# M4K0A register map
File version: 0.1
Registers are 32-bit, read-write, reset 0x0 unless marked. A register's access mark holds for its fields unless they carry their own. Offsets are from the block's base; [hi:lo] are bit positions; {n}, {i} and the like mark numbered series.

## SIWD
Base 0x400BB400
0x00 PRO reset 0x1E — SIWD Protect register
  [7:0] PROTECT
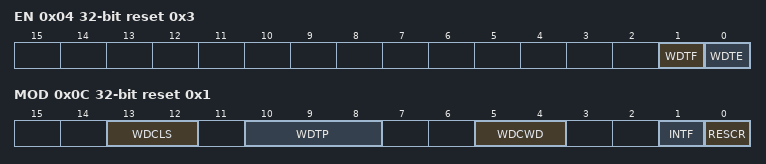
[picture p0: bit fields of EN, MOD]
0x04 EN reset 0x3 — SIWD Enable register
  [1] WDTF ro, [0] WDTE
0x08 CR wo (reset mask 0xFFFFFF00) — SIWD Control register
  [7:0] WDCR
0x0C MOD reset 0x1 — SIWD Mode register
  [13:12] WDCLS, [10:8] WDTP, [5:4] WDCWD, [1] INTF, [0] RESCR
0x10 MONI ro (reset mask 0xC0000000) — SIWD Monitor register
  [29:0] MONI
0x14 OSCCR — SIWD Oscillation control register
  [0] OSCPRO

## DNF
Base 0x400BB600
0x00 CKCR — DNF clock Control register
  [2:0] NFCKS
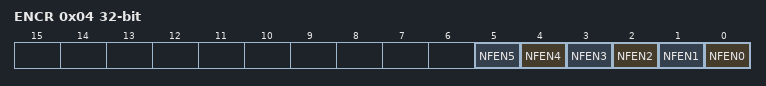
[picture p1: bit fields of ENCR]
0x04 ENCR — DNF Enable register
  [n] NFEN{n} (n=0..5)

## TSEL — TRGSEL
Base 0x400BB800
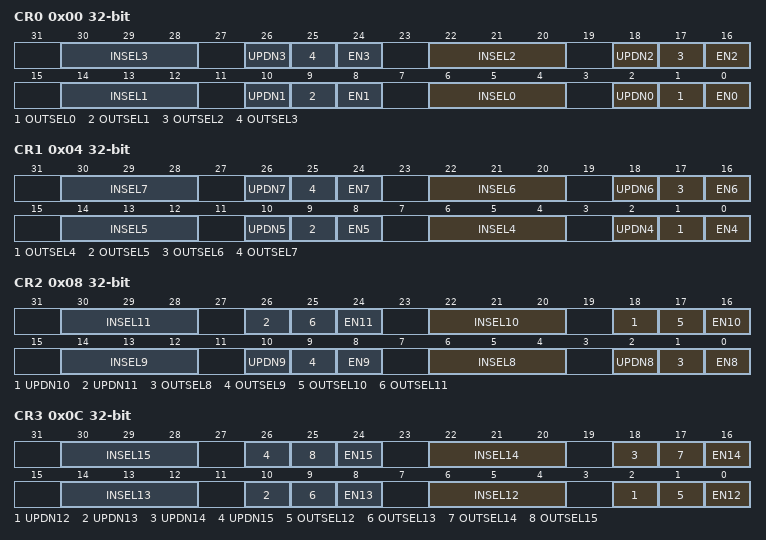
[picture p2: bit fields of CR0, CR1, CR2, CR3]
0x00 CR0 — TRGSEL Control register 0
  [8n+6:8n+4] INSEL{n} (n=0..3), [8n+2] UPDN{n} (n=0..3), [8n+1] OUTSEL{n} (n=0..3), [8n] EN{n} (n=0..3)
0x04 CR1 — TRGSEL Control register 1
  [8n-26:8n-28] INSEL{n} (n=4..7), [8n-30] UPDN{n} (n=4..7), [8n-31] OUTSEL{n} (n=4..7), [8n-32] EN{n} (n=4..7)
0x08 CR2 — TSEL Control register 2
  [8n-58:8n-60] INSEL{n} (n=8..11), [8n-62] UPDN{n} (n=8..11), [8n-63] OUTSEL{n} (n=8..11), [8n-64] EN{n} (n=8..11)
0x0C CR3 — TRGSEL Control register 3
  [8n-90:8n-92] INSEL{n} (n=12..15), [8n-94] UPDN{n} (n=12..15), [8n-95] OUTSEL{n} (n=12..15), [8n-96] EN{n} (n=12..15)
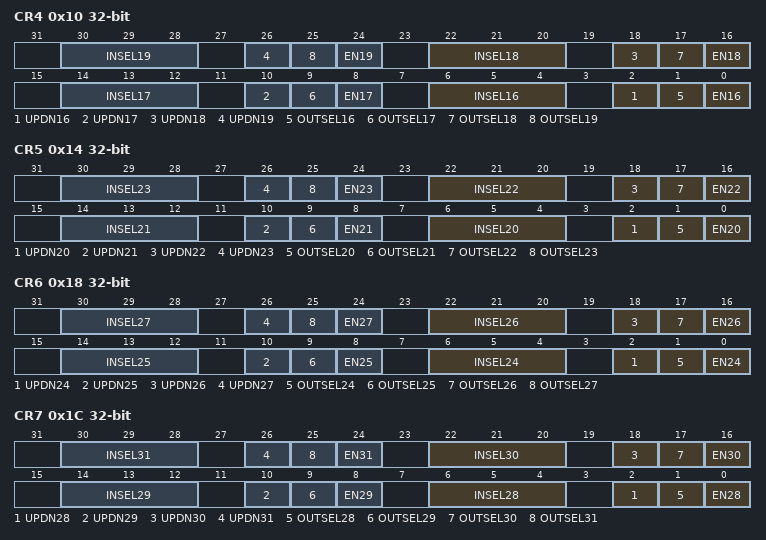
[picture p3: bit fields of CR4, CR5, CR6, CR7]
0x10 CR4 — TRGSEL Control register 4
  [8n-122:8n-124] INSEL{n} (n=16..19), [8n-126] UPDN{n} (n=16..19), [8n-127] OUTSEL{n} (n=16..19), [8n-128] EN{n} (n=16..19)
0x14 CR5 — TRGSEL Control register 5
  [8n-154:8n-156] INSEL{n} (n=20..23), [8n-158] UPDN{n} (n=20..23), [8n-159] OUTSEL{n} (n=20..23), [8n-160] EN{n} (n=20..23)
0x18 CR6 — TRGSEL Control register 6
  [8n-186:8n-188] INSEL{n} (n=24..27), [8n-190] UPDN{n} (n=24..27), [8n-191] OUTSEL{n} (n=24..27), [8n-192] EN{n} (n=24..27)
0x1C CR7 — TRGSEL Control register 7
  [8n-218:8n-220] INSEL{n} (n=28..31), [8n-222] UPDN{n} (n=28..31), [8n-223] OUTSEL{n} (n=28..31), [8n-224] EN{n} (n=28..31)
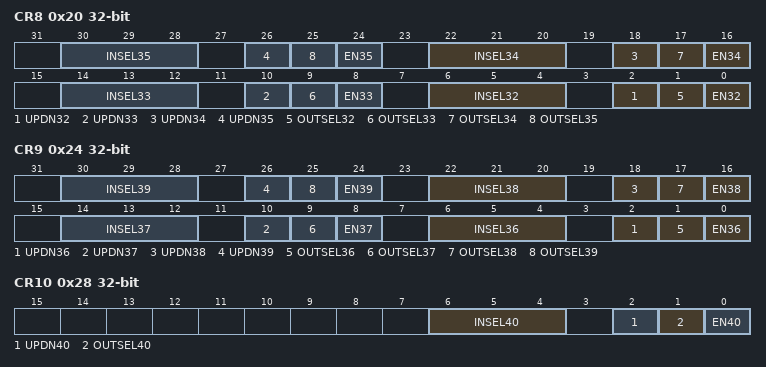
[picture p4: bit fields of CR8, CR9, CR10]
0x20 CR8 — TRGSEL Control register 8
  [8n-250:8n-252] INSEL{n} (n=32..35), [8n-254] UPDN{n} (n=32..35), [8n-255] OUTSEL{n} (n=32..35), [8n-256] EN{n} (n=32..35)
0x24 CR9 — TRGSEL Control register 9
  [8n-282:8n-284] INSEL{n} (n=36..39), [8n-286] UPDN{n} (n=36..39), [8n-287] OUTSEL{n} (n=36..39), [8n-288] EN{n} (n=36..39)
0x28 CR10 — TRGSEL Control register 10
  [6:4] INSEL40, [2] UPDN40, [1] OUTSEL40, [0] EN40

## RPAR — RAM Parity
Base 0x400BBB00
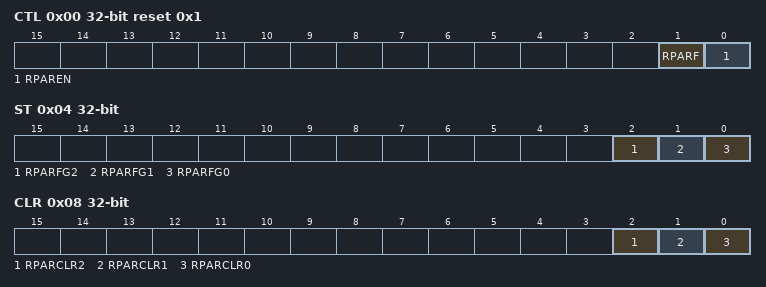
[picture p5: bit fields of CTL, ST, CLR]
0x00 CTL reset 0x1 — RAMM Parity control register
  [1] RPARF, [0] RPAREN
0x04 ST ro — RAMM Parity status register
  [2] RPARFG2, [1] RPARFG1, [0] RPARFG0
0x08 CLR wo — RAMM Parity status clear register
  [2] RPARCLR2, [1] RPARCLR1, [0] RPARCLR0
{0xC+4i} EAD{i} ro (i=0..2) — RAMM Parity Error address register {i}
  [31:0] RPAREADD{i}

## CRC
Base 0x400BBC00
0x00 DIN — CRC input data register
  [31:0] CRCDIN
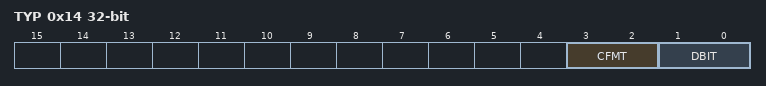
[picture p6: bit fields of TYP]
0x14 TYP — CRC data type register
  [3:2] CFMT, [1:0] DBIT
0x2C CLC reset 0xFFFFFFFF — CRC calculation result register
  [31:0] CRCCLC

## AMP
Base 0x400BC000
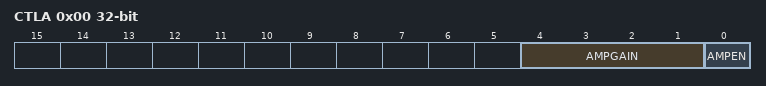
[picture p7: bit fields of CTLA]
0x00 CTLA — AMP control register A
  [4:1] AMPGAIN, [0] AMPEN

## PD — Port D
Base 0x400C0300
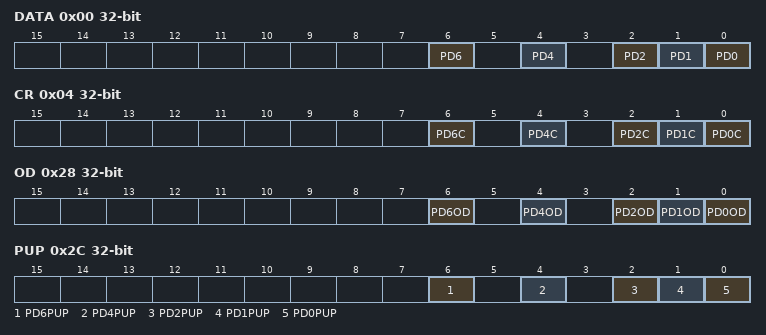
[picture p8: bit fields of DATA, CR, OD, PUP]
0x00 DATA — PD Data Register
  [6] PD6, [4] PD4, [2] PD2, [1] PD1, [0] PD0
0x04 CR — PD Control Register
  [6] PD6C, [4] PD4C, [2] PD2C, [1] PD1C, [0] PD0C
0x18 FR5 — PD Function Register 5
  [6] PD6F5
0x28 OD — PD Open Drain Control Register
  [6] PD6OD, [4] PD4OD, [2] PD2OD, [1] PD1OD, [0] PD0OD
0x2C PUP — PD Pull-up Control Register
  [6] PD6PUP, [4] PD4PUP, [2] PD2PUP, [1] PD1PUP, [0] PD0PUP
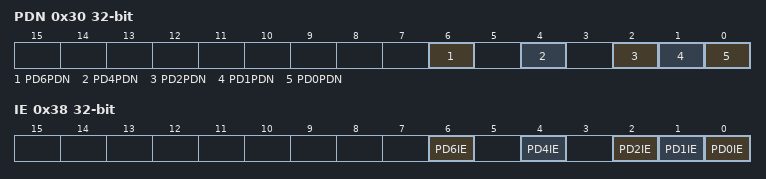
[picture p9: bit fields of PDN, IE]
0x30 PDN — PD Pull-Down Control Register
  [6] PD6PDN, [4] PD4PDN, [2] PD2PDN, [1] PD1PDN, [0] PD0PDN
0x38 IE — PD Input Enable Control Register
  [6] PD6IE, [4] PD4IE, [2] PD2IE, [1] PD1IE, [0] PD0IE

## PE — Port E
Base 0x400C0400
0x00 DATA — PE Data Register
  [5] PE5
0x04 CR — PE Control Register
  [5] PE5C
0x28 OD — PE Open Drain Control Register
  [5] PE5OD
0x2C PUP — PE Pull-up Control Register
  [5] PE5PUP
0x30 PDN — PE Pull-Down Control Register
  [5] PE5PDN
0x38 IE — PE Input Enable Control Register
  [5] PE5IE
